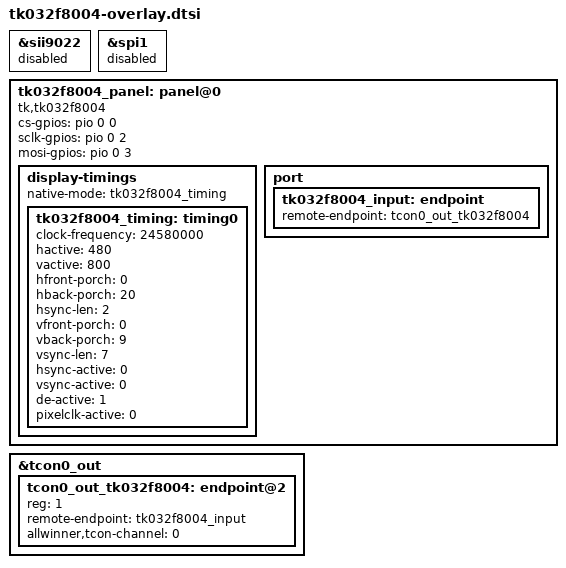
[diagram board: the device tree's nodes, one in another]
/* Candidate only: merge into the active board DTS on a dedicated branch. */

&sii9022 {
	status = "disabled";
};

&spi1 {
	status = "disabled";
};

tk032f8004_panel: panel@0 {
	compatible = "tk,tk032f8004";
	status = "okay";

	/* Shared command bus: PA2/PA3 are released after initialization. */
	cs-gpios = <&pio 0 0 GPIO_ACTIVE_HIGH>;
	sclk-gpios = <&pio 0 2 GPIO_ACTIVE_HIGH>;
	mosi-gpios = <&pio 0 3 GPIO_ACTIVE_HIGH>;

	display-timings {
		native-mode = <&tk032f8004_timing>;
		tk032f8004_timing: timing0 {
			/* LG4573A native scan: 480 RGB source columns x 800 gate rows. */
			clock-frequency = <24580000>; /* 502 x 816 x 60 Hz */
			hactive = <480>;
			vactive = <800>;
			/* 800x480 is an upper-layer rotated logical presentation. */
			hfront-porch = <0>;
			hback-porch = <20>;
			hsync-len = <2>;
			vfront-porch = <0>;
			vback-porch = <9>;
			vsync-len = <7>;
			hsync-active = <0>;
			vsync-active = <0>;
			de-active = <1>;
			pixelclk-active = <0>;
		};
	};

	port {
		tk032f8004_input: endpoint {
			remote-endpoint = <&tcon0_out_tk032f8004>;
		};
	};
};

&tcon0_out {
	tcon0_out_tk032f8004: endpoint@2 {
		reg = <1>;
		remote-endpoint = <&tk032f8004_input>;
		allwinner,tcon-channel = <0>;
	};
};
